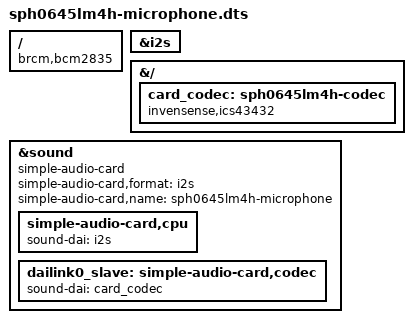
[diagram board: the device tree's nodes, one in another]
/dts-v1/;
/plugin/;

/ {
	compatible = "brcm,bcm2835";
};

&i2s {
	status = "okay";
};

&{/} {
	card_codec: sph0645lm4h-codec {
        #sound-dai-cells = <0>;
        compatible = "invensense,ics43432";
        status = "okay";
    };
};

&sound {
	compatible = "simple-audio-card";
    simple-audio-card,format = "i2s";
    simple-audio-card,name = "sph0645lm4h-microphone";
    status = "okay";
    simple-audio-card,cpu {
        sound-dai = <&i2s>;
    };
    dailink0_slave: simple-audio-card,codec {
        sound-dai = <&card_codec>;
    };
};
